# S32K146 register map
Vendor: NXP; Series: S32K; File version: 1.6
CPU: CM4 r0p1, little endian, MPU, FPU, 4 interrupt priority bits
Registers are 32-bit, read-write, reset 0x0 unless marked. A register's access mark holds for its fields unless they carry their own. Offsets are from the block's base; [hi:lo] are bit positions; {n}, {i} and the like mark numbered series; 'fields as' and 'values as' point back to an identical list.

## SIM — System Integration Module
Base 0x40048000; register names take the prefix SIM_
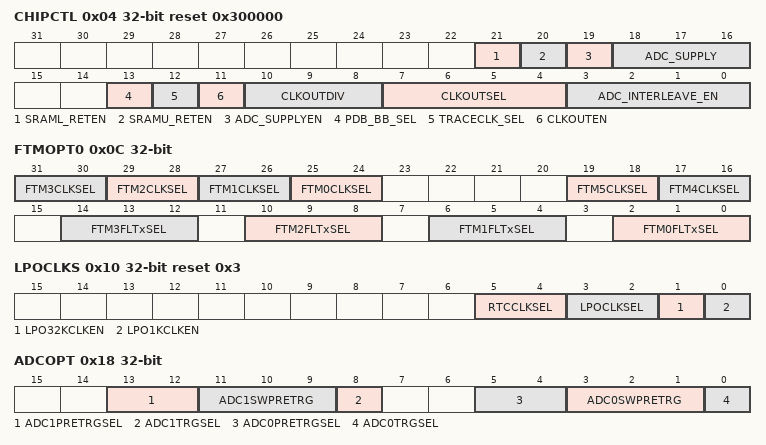
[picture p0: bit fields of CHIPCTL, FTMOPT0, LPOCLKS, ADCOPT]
0x04 CHIPCTL reset 0x300000 — Chip Control register
  [21] SRAML_RETEN
    0=SRAML contents are retained across resets; 1=No SRAML retention
  [20] SRAMU_RETEN
    0=SRAMU contents are retained across resets; 1=No SRAMU retention
  [19] ADC_SUPPLYEN
    0=Disable internal supply monitoring; 1=Enable internal supply monitoring
  [18:16] ADC_SUPPLY
    0=5 V input VDD supply (VDD); 1=5 V input analog supply (VDDA); 2=ADC Reference Supply (VREFH); 3=3.3 V Oscillator Regulator Output (VDD_3V); 4=3.3 V flash regulator output (VDD_flash_3V); 5=1.2 V core regulator output (VDD_LV)
  [13] PDB_BB_SEL — PDB back-to-back select
    0=PDB0 channel 0 back-to-back operation with ADC0 COCO[7:0] and PDB1 channel 0 back-to-back operation with ADC1 COCO[7:0]; 1=Channel 0 of PDB0 and PDB1 back-to-back operation with COCO[7:0] of ADC0 and ADC1
  [12] TRACECLK_SEL — Debug trace clock select
    0=Core clock; 1=Platform clock
  [11] CLKOUTEN — CLKOUT enable
    0=Clockout disable; 1=Clockout enable
  [10:8] CLKOUTDIV — CLKOUT Divide Ratio
    {v}=Divide by {v+1} (v=0..7)
  [7:4] CLKOUTSEL — CLKOUT Select
    0=SCG CLKOUT; 2=SOSC DIV2 CLK; 4=SIRC DIV2 CLK; 5=For S32K148: QSPI SFIF_CLK_HYP: Divide by 2 clock (configured through SCLKCONFIG[5]) for HyperRAM going to sfif clock to QSPI; For others: Reserved; 6=FIRC DIV2 CLK; 7=HCLK; 8=SPLL DIV2 CLK; 9=BUS_CLK; 10=LPO128K_CLK; 11=For S32K148: QSPI IPG_CLK; For others: Reserved; 12=LPO_CLK as selected by SIM_LPOCLKS[LPOCLKSEL]; 13=For S32K148: QSPI IPG_CLK_SFIF; For others: Reserved; 14=RTC_CLK as selected by SIM_LPOCLKS[RTCCLKSEL]; 15=For S32K148: QSPI IPG_CLK_2XSFIF; For others: Reserved
  [3:0] ADC_INTERLEAVE_EN — ADC interleave channel enable
    0=Interleaving disabled. No channel pair interleaved. Interleaved channels are individually connected to pins. PTC0 is connected to ADC0_SE8. PTC1 is connected to ADC0_SE9. PTB15 is connected to ADC1_SE14. PTB16 is connected to ADC1_SE15. PTB0 is connected to ADC0_SE4. PTB1 is connected to ADC0_SE5. PTB13 is connected to ADC1_SE8. PTB14 is connected to ADC1_SE9.; 0b1xxx=PTB14 to ADC1_SE9 and ADC0_SE9; 0bx1xx=PTB13 to ADC1_SE8 and ADC0_SE8; 0bxx1x=PTB1 to ADC0_SE5 and ADC1_SE15; 0bxxx1=PTB0 to ADC0_SE4 and ADC1_SE14
0x0C FTMOPT0 — FTM Option Register 0
  [2n+25:2n+24] FTM{n}CLKSEL (n=0..3) — FTM{n} External Clock Pin Select
    0=FTM{n} external clock driven by TCLK0 pin; 1=FTM{n} external clock driven by TCLK1 pin; 2=FTM{n} external clock driven by TCLK2 pin; 3=No clock input
  [19:18] FTM5CLKSEL — FTM5 External Clock Pin Select
    0=FTM5 external clock driven by TCLK0 pin; 1=FTM5 external clock driven by TCLK1 pin; 2=FTM5 external clock driven by TCLK2 pin; 3=No clock input
  [17:16] FTM4CLKSEL — FTM4 External Clock Pin Select
    0=FTM4 external clock driven by TCLK0 pin; 1=FTM4 external clock driven by TCLK1 pin; 2=FTM4 external clock driven by TCLK2 pin; 3=No clock input
  [4n+2:4n] FTM{n}FLTxSEL (n=0..3) — FTM{n} Fault X Select
    0=FTM{n}_FLTx pin; 1=TRGMUX_FTM{n} out
0x10 LPOCLKS reset 0x3 — LPO Clock Select Register
  [5:4] RTCCLKSEL — 32 kHz clock source select
    0=SOSCDIV1_CLK; 1=32 kHz LPO_CLK; 2=RTC_CLKIN clock; 3=FIRCDIV1_CLK
  [3:2] LPOCLKSEL — LPO clock source select
    0=128 kHz LPO_CLK; 1=No clock; 2=32 kHz LPO_CLK which is derived from the 128 kHz LPO_CLK; 3=1 kHz LPO_CLK which is derived from the 128 kHz LPO_CLK
  [1] LPO32KCLKEN — 32 kHz LPO_CLK enable
    0=Disable 32 kHz LPO_CLK output; 1=Enable 32 kHz LPO_CLK output
  [0] LPO1KCLKEN — 1 kHz LPO_CLK enable
    0=Disable 1 kHz LPO_CLK output; 1=Enable 1 kHz LPO_CLK output
0x18 ADCOPT — ADC Options Register
  [13:12] ADC1PRETRGSEL — ADC1 pretrigger source select
    0=PDB pretrigger (default); 1=TRGMUX pretrigger; 2=Software pretrigger
  [11:9] ADC1SWPRETRG — ADC1 software pretrigger sources
    0=Software pretrigger disabled; {v}=Software pretrigger {v-4} (v=4..7)
  [8] ADC1TRGSEL — ADC1 trigger source select
    0=PDB output; 1=TRGMUX output
  [5:4] ADC0PRETRGSEL — ADC0 pretrigger source select
    values as ADC1PRETRGSEL
  [3:1] ADC0SWPRETRG — ADC0 software pretrigger sources
    values as ADC1SWPRETRG
  [0] ADC0TRGSEL — ADC0 trigger source select
    0=PDB output; 1=TRGMUX output
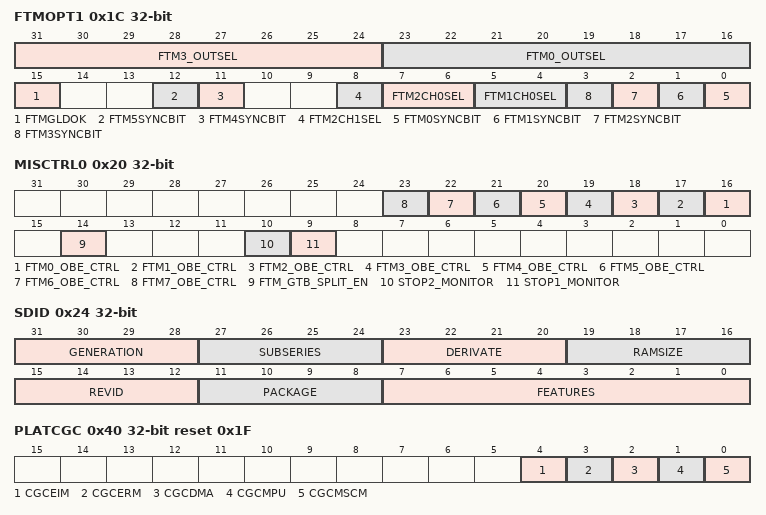
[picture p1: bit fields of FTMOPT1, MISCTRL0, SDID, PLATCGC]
0x1C FTMOPT1 — FTM Option Register 1
  [31:24] FTM3_OUTSEL — FTM3 channel modulation select with FTM2_CH1
    0=No modulation with FTM2_CH1; 1=Modulation with FTM2_CH1
  [23:16] FTM0_OUTSEL — FTM0 channel modulation select with FTM1_CH1
    0=No modulation with FTM1_CH1; 1=Modulation with FTM1_CH1
  [15] FTMGLDOK — FTM global load enable
    0=FTM Global load mechanism disabled; 1=FTM Global load mechanism enabled
  [12] FTM5SYNCBIT
  [11] FTM4SYNCBIT
  [8] FTM2CH1SEL — FTM2 CH1 Select
    0=FTM2_CH1 input; 1=exclusive OR of FTM2_CH0,FTM2_CH1,and FTM1_CH1
  [7:6] FTM2CH0SEL — FTM2 CH0 Select
    0=FTM2_CH0 input; 1=CMP0 output
  [5:4] FTM1CH0SEL — FTM1 CH0 Select
    0=FTM1_CH0 input; 1=CMP0 output
  [n] FTM{n}SYNCBIT (n=0..3)
0x20 MISCTRL0 — Miscellaneous control register 0
  [n+16] FTM{n}_OBE_CTRL (n=0..7) — FTM{n} OBE CTRL bit
    0=The FTM channel output is put to safe state when the FTM counter is enabled and the FTM channel output is enabled by Fault Control (FTM_MODE[FAULTM]!=2'b00 and FTM_FLTCTRL[FSTATE]=1'b0) and PWM is enabled (FTM_SC[PWMENn] = 1'b1). Otherwise the channel output is tristated.; 1=The FTM channel output state is retained when the channel is in output mode. The output channel is tristated when the channel is in input capture [DECAPEN=1'b0, COMBINE=1'b0, MSnB:MSnA=2'b00] or dual edge capture mode [DECAPEN=1'b1].
  [14] FTM_GTB_SPLIT_EN — FTM GTB split enable/disable bit
    0=All the FTMs have a single global time-base; 1=FTM0-3 have a common time-base and others have a different common time-base. Please refer 'FTM global time base' in FTM chapter for implementation details.
  [10] STOP2_MONITOR — STOP2 monitor bit
    0=System clock enabled or STOP2 entry aborted; 1=STOP2 entry successful
  [9] STOP1_MONITOR — STOP1 monitor bit
    0=Bus clock enabled or STOP1 entry aborted; 1=STOP1 entry successful
0x24 SDID ro reset not defined — System Device Identification Register
  [31:28] GENERATION — S32K product series generation
  [27:24] SUBSERIES
  [23:20] DERIVATE
  [19:16] RAMSIZE
    11=192 KB (S32K148), 96 KB (S32K146), Reserved (others); 13=48 KB (S32K144), Reserved (others); 15=256 KB (S32K148), 128 KB (S32K146), 64 KB (S32K144), 32 KB (S32K142), 25 KB (S32K118), 17 KB (S32K116)
  [15:12] REVID — Device revision number
  [11:8] PACKAGE
    2=48 LQFP; 3=64 LQFP; 4=100 LQFP; 6=144 LQFP; 7=176 LQFP; 8=100 MAP BGA
  [7:0] FEATURES
0x40 PLATCGC reset 0x1F — Platform Clock Gating Control Register
  [all] fields
    0=Clock disabled; 1=Clock enabled
  [4] CGCEIM — EIM Clock Gating Control
  [3] CGCERM — ERM Clock Gating Control
  [2] CGCDMA — DMA Clock Gating Control
  [1] CGCMPU — MPU Clock Gating Control
  [0] CGCMSCM — MSCM Clock Gating Control
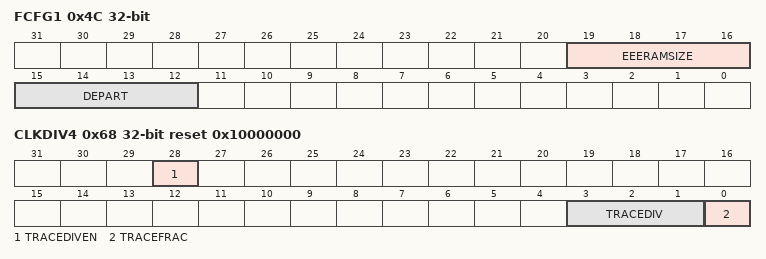
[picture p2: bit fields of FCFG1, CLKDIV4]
0x4C FCFG1 reset not defined — Flash Configuration Register 1
  [19:16] EEERAMSIZE ro — EEE SRAM SIZE
    2=4 KB; 3=2 KB; 4=1 KB; 5=512 Bytes; 6=256 Bytes; 7=128 Bytes; 8=64 Bytes; 9=32 Bytes; 15=0 Bytes
  [15:12] DEPART ro — FlexNVM partition
0x54 UIDH ro reset not defined — Unique Identification Register High
  [31:0] UID127_96 — Unique Identification
0x58 UIDMH ro reset not defined — Unique Identification Register Mid-High
  [31:0] UID95_64 — Unique Identification
0x5C UIDML ro reset not defined — Unique Identification Register Mid Low
  [31:0] UID63_32 — Unique Identification
0x60 UIDL ro reset not defined — Unique Identification Register Low
  [31:0] UID31_0 — Unique Identification
0x68 CLKDIV4 reset 0x10000000 — System Clock Divider Register 4
  [28] TRACEDIVEN — Debug Trace Divider control
    0=Debug trace divider disabled; 1=Debug trace divider enabled
  [3:1] TRACEDIV — Trace Clock Divider value To configure TRACEDIV, you must first disable TRACEDIVEN, then enable it after setting TRACEDIV.
  [0] TRACEFRAC — Trace Clock Divider fraction To configure TRACEDIV and TRACEFRAC, you must first clear TRACEDIVEN to disable the trace clock divide function.
0x6C MISCTRL1 — Miscellaneous Control register 1
  [0] SW_TRG — Software trigger to TRGMUX. Writing to this bit generates software trigger to peripherals through TRGMUX (Refer to Figure: Trigger interconnectivity).

## Notices in the file
Redistribution and use in source and binary forms, with or without modification,
are permitted provided that the following conditions are met:
o Redistributions of source code must retain the above copyright notice, this list
of conditions and the following disclaimer.
o Redistributions in binary form must reproduce the above copyright notice, this
list of conditions and the following disclaimer in the documentation and/or
other materials provided with the distribution.
o Neither the name of Freescale Semiconductor, Inc. nor the names of its
contributors may be used to endorse or promote products derived from this
software without specific prior written permission.
THIS SOFTWARE IS PROVIDED BY THE COPYRIGHT HOLDERS AND CONTRIBUTORS "AS IS" AND
ANY EXPRESS OR IMPLIED WARRANTIES, INCLUDING, BUT NOT LIMITED TO, THE IMPLIED
WARRANTIES OF MERCHANTABILITY AND FITNESS FOR A PARTICULAR PURPOSE ARE
DISCLAIMED. IN NO EVENT SHALL THE COPYRIGHT HOLDER OR CONTRIBUTORS BE LIABLE FOR
ANY DIRECT, INDIRECT, INCIDENTAL, SPECIAL, EXEMPLARY, OR CONSEQUENTIAL DAMAGES
(INCLUDING, BUT NOT LIMITED TO, PROCUREMENT OF SUBSTITUTE GOODS OR SERVICES;
LOSS OF USE, DATA, OR PROFITS; OR BUSINESS INTERRUPTION) HOWEVER CAUSED AND ON
ANY THEORY OF LIABILITY, WHETHER IN CONTRACT, STRICT LIABILITY, OR TORT
(INCLUDING NEGLIGENCE OR OTHERWISE) ARISING IN ANY WAY OUT OF THE USE OF THIS
SOFTWARE, EVEN IF ADVISED OF THE POSSIBILITY OF SUCH DAMAGE.
